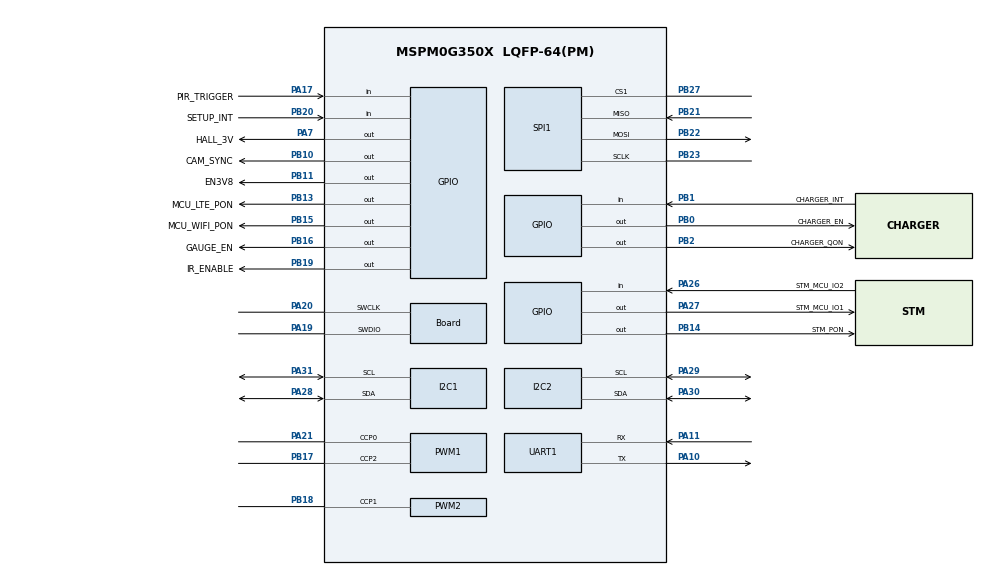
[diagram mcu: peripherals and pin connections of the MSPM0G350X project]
/**
 * @cliArgs --device "MSPM0G350X" --part "Default" --package "LQFP-64(PM)" --product "mspm0_sdk@2.09.00.01"
 * @versions {"tool":"1.25.0+4268"}
 */

/**
 * Import the modules used in this configuration.
 */
const Board  = scripting.addModule("/ti/driverlib/Board");
const GPIO   = scripting.addModule("/ti/driverlib/GPIO", {}, false);
const GPIO1  = GPIO.addInstance();
const GPIO2  = GPIO.addInstance();
const GPIO3  = GPIO.addInstance();
const I2C    = scripting.addModule("/ti/driverlib/I2C", {}, false);
const I2C1   = I2C.addInstance();
const I2C2   = I2C.addInstance();
const PWM    = scripting.addModule("/ti/driverlib/PWM", {}, false);
const PWM1   = PWM.addInstance();
const PWM2   = PWM.addInstance();
const RTC    = scripting.addModule("/ti/driverlib/RTC");
const SPI    = scripting.addModule("/ti/driverlib/SPI", {}, false);
const SPI1   = SPI.addInstance();
const SYSCTL = scripting.addModule("/ti/driverlib/SYSCTL");
const UART   = scripting.addModule("/ti/driverlib/UART", {}, false);
const UART1  = UART.addInstance();

/**
 * Write custom configuration values to the imported modules.
 */
const mux5       = system.clockTree["EXLFMUX"];
mux5.inputSelect = "EXLFMUX_XTAL";

const pinFunction6     = system.clockTree["LFXT"];
pinFunction6.enable    = true;
pinFunction6.inputFreq = 32.768;

Board.peripheral.swclkPin.$assign = "PA20";
Board.peripheral.swdioPin.$assign = "PA19";

GPIO1.$name                              = "EXTERNAL_INTERRUPT";
GPIO1.associatedPins.create(4);
GPIO1.associatedPins[0].$name            = "CHARGER_INT";
GPIO1.associatedPins[0].direction        = "INPUT";
GPIO1.associatedPins[0].assignedPin      = "any";
GPIO1.associatedPins[0].ioStructure      = "SD";
GPIO1.associatedPins[0].polarity         = "FALL";
GPIO1.associatedPins[0].pin.$assign      = "PB1";
GPIO1.associatedPins[1].$name            = "SETUP_INT";
GPIO1.associatedPins[1].direction        = "INPUT";
GPIO1.associatedPins[1].assignedPort     = "PORTB";
GPIO1.associatedPins[1].assignedPin      = "any";
GPIO1.associatedPins[1].interruptEn      = true;
GPIO1.associatedPins[1].polarity         = "FALL";
GPIO1.associatedPins[1].pin.$assign      = "PB20";
GPIO1.associatedPins[2].$name            = "STM_MCU_IO2";
GPIO1.associatedPins[2].direction        = "INPUT";
GPIO1.associatedPins[2].internalResistor = "PULL_DOWN";
GPIO1.associatedPins[2].interruptEn      = true;
GPIO1.associatedPins[2].polarity         = "RISE_FALL";
GPIO1.associatedPins[2].pin.$assign      = "PA26";
GPIO1.associatedPins[3].$name            = "PIR_TRIGGER";
GPIO1.associatedPins[3].direction        = "INPUT";
GPIO1.associatedPins[3].ioStructure      = "SDW";
GPIO1.associatedPins[3].assignedPort     = "PORTA";
GPIO1.associatedPins[3].interruptEn      = true;
GPIO1.associatedPins[3].polarity         = "FALL";
GPIO1.associatedPins[3].pin.$assign      = "PA17";

GPIO2.$name                          = "DIGITAL_OUTPUT_PORTB";
GPIO2.port                           = "PORTB";
GPIO2.associatedPins.create(9);
GPIO2.associatedPins[0].$name        = "CHARGER_EN";
GPIO2.associatedPins[0].ioStructure  = "SD";
GPIO2.associatedPins[0].assignedPin  = "0";
GPIO2.associatedPins[0].initialValue = "SET";
GPIO2.associatedPins[0].pin.$assign  = "PB0";
GPIO2.associatedPins[1].$name        = "CHARGER_QON";
GPIO2.associatedPins[1].ioStructure  = "SD";
GPIO2.associatedPins[1].assignedPin  = "2";
GPIO2.associatedPins[1].initialValue = "SET";
GPIO2.associatedPins[1].pin.$assign  = "PB2";
GPIO2.associatedPins[2].assignedPin  = "11";
GPIO2.associatedPins[2].ioStructure  = "SD";
GPIO2.associatedPins[2].$name        = "EN3V8";
GPIO2.associatedPins[2].pin.$assign  = "PB11";
GPIO2.associatedPins[3].$name        = "MCU_LTE_PON";
GPIO2.associatedPins[3].ioStructure  = "SD";
GPIO2.associatedPins[3].assignedPin  = "13";
GPIO2.associatedPins[3].pin.$assign  = "PB13";
GPIO2.associatedPins[4].$name        = "STM_PON";
GPIO2.associatedPins[4].ioStructure  = "SD";
GPIO2.associatedPins[4].assignedPin  = "14";
GPIO2.associatedPins[4].pin.$assign  = "PB14";
GPIO2.associatedPins[5].ioStructure  = "SD";
GPIO2.associatedPins[5].assignedPin  = "15";
GPIO2.associatedPins[5].$name        = "MCU_WIFI_PON";
GPIO2.associatedPins[5].pin.$assign  = "PB15";
GPIO2.associatedPins[6].$name        = "CAM_SYNC";
GPIO2.associatedPins[6].ioStructure  = "SD";
GPIO2.associatedPins[6].assignedPin  = "10";
GPIO2.associatedPins[6].pin.$assign  = "PB10";
GPIO2.associatedPins[7].$name        = "GAUGE_EN";
GPIO2.associatedPins[7].pin.$assign  = "PB16";
GPIO2.associatedPins[8].$name        = "IR_ENABLE";
GPIO2.associatedPins[8].pin.$assign  = "PB19";

GPIO3.$name                              = "DIGITAL_OUTPUT_PORTA";
GPIO3.port                               = "PORTA";
GPIO3.associatedPins.create(2);
GPIO3.associatedPins[0].$name            = "HALL_3V";
GPIO3.associatedPins[0].pin.$assign      = "PA7";
GPIO3.associatedPins[1].$name            = "STM_MCU_IO1";
GPIO3.associatedPins[1].internalResistor = "PULL_DOWN";
GPIO3.associatedPins[1].pin.$assign      = "PA27";

I2C1.$name                         = "I2C_0";
I2C1.basicEnableController         = true;
I2C1.intController                 = ["ARBITRATION_LOST","NACK","RXFIFO_TRIGGER","RX_DONE","TXFIFO_TRIGGER","TX_DONE"];
I2C1.peripheral.$assign            = "I2C0";
I2C1.peripheral.sdaPin.$assign     = "PA28";
I2C1.peripheral.sclPin.$assign     = "PA31";
I2C1.sdaPinConfig.$name            = "ti_driverlib_gpio_GPIOPinGeneric9";
I2C1.sdaPinConfig.internalResistor = "PULL_UP";
I2C1.sdaPinConfig.enableConfig     = true;
I2C1.sclPinConfig.$name            = "ti_driverlib_gpio_GPIOPinGeneric10";
I2C1.sclPinConfig.internalResistor = "PULL_UP";
I2C1.sclPinConfig.enableConfig     = true;

I2C2.$name                         = "I2C_1";
I2C2.basicEnableController         = true;
I2C2.intController                 = ["ARBITRATION_LOST","NACK","RXFIFO_TRIGGER","RX_DONE","TXFIFO_TRIGGER","TX_DONE"];
I2C2.peripheral.$assign            = "I2C1";
I2C2.peripheral.sdaPin.$assign     = "PA30";
I2C2.peripheral.sclPin.$assign     = "PA29";
I2C2.sdaPinConfig.$name            = "ti_driverlib_gpio_GPIOPinGeneric11";
I2C2.sdaPinConfig.internalResistor = "PULL_UP";
I2C2.sdaPinConfig.enableConfig     = true;
I2C2.sclPinConfig.$name            = "ti_driverlib_gpio_GPIOPinGeneric12";
I2C2.sclPinConfig.internalResistor = "PULL_UP";
I2C2.sclPinConfig.enableConfig     = true;

PWM1.$name                              = "BOOST_CONTROL";
PWM1.clockDivider                       = 8;
PWM1.timerCount                         = 100;
PWM1.ccIndex                            = [0,2];
PWM1.PWM_CHANNEL_0.$name                = "ti_driverlib_pwm_PWMTimerCC0";
PWM1.PWM_CHANNEL_0.ccValue              = 99;
PWM1.ccp0PinConfig.direction            = scripting.forceWrite("OUTPUT");
PWM1.ccp0PinConfig.hideOutputInversion  = scripting.forceWrite(false);
PWM1.ccp0PinConfig.onlyInternalResistor = scripting.forceWrite(false);
PWM1.ccp0PinConfig.passedPeripheralType = scripting.forceWrite("Digital");
PWM1.ccp0PinConfig.$name                = "ti_driverlib_gpio_GPIOPinGeneric0";
PWM1.ccp0PinConfig.enableConfig         = true;
PWM1.ccp0PinConfig.internalResistor     = "PULL_DOWN";
PWM1.peripheral.ccp0Pin.$assign         = "PA21";
PWM1.peripheral.ccp2Pin.$assign         = "PB17";
PWM1.PWM_CHANNEL_2.$name                = "ti_driverlib_pwm_PWMTimerCC1";
PWM1.PWM_CHANNEL_2.ccValue              = 99;
PWM1.ccp2PinConfig.$name                = "ti_driverlib_gpio_GPIOPinGeneric1";

PWM2.$name                              = "FLASH_CONTROL";
PWM2.clockDivider                       = 8;
PWM2.timerCount                         = 20000;
PWM2.pwmMode                            = "EDGE_ALIGN_UP";
PWM2.ccIndex                            = [1];
PWM2.ccp1PinConfig.direction            = scripting.forceWrite("OUTPUT");
PWM2.ccp1PinConfig.hideOutputInversion  = scripting.forceWrite(false);
PWM2.ccp1PinConfig.onlyInternalResistor = scripting.forceWrite(false);
PWM2.ccp1PinConfig.passedPeripheralType = scripting.forceWrite("Digital");
PWM2.ccp1PinConfig.$name                = "ti_driverlib_gpio_GPIOPinGeneric2";
PWM2.peripheral.$assign                 = "TIMA1";
PWM2.peripheral.ccp1Pin.$assign         = "PB18";
PWM2.PWM_CHANNEL_1.$name                = "ti_driverlib_pwm_PWMTimerCC2";
PWM2.PWM_CHANNEL_1.dutyCycle            = 20;

RTC.enIntervalAlarm   = true;
RTC.enabledInterrupts = ["INTERVAL_ALARM","PRESCALER1"];
RTC.enPerAlarm1       = true;
RTC.perAlarm1Divider  = "DIVIDE_128";
RTC.enableClock       = true;
RTC.calHour           = 2;
RTC.calMin            = 1;
RTC.calSec            = 1;
RTC.calDOW            = "4";
RTC.calMonth          = "6";
RTC.calYear           = 2000;

SPI1.$name                                 = "SPI_1";
SPI1.peripheralChipSelect                  = "1";
SPI1.rxFifoThreshold                       = "DL_SPI_RX_FIFO_LEVEL_ONE_FRAME";
SPI1.txFifoThreshold                       = "DL_SPI_TX_FIFO_LEVEL_ONE_FRAME";
SPI1.enabledInterrupts                     = ["DMA_DONE_RX","DMA_DONE_TX","TX_EMPTY"];
SPI1.enabledDMAEvent1Triggers              = "DL_SPI_DMA_INTERRUPT_RX";
SPI1.enabledDMAEvent2Triggers              = "DL_SPI_DMA_INTERRUPT_TX";
SPI1.chipSelect                            = ["1"];
SPI1.targetBitRate                         = 10000;
SPI1.sclkPinConfig.direction               = scripting.forceWrite("OUTPUT");
SPI1.sclkPinConfig.onlyInternalResistor    = scripting.forceWrite(false);
SPI1.sclkPinConfig.passedPeripheralType    = scripting.forceWrite("Digital");
SPI1.sclkPinConfig.$name                   = "ti_driverlib_gpio_GPIOPinGeneric5";
SPI1.mosiPinConfig.direction               = scripting.forceWrite("OUTPUT");
SPI1.mosiPinConfig.hideOutputInversion     = scripting.forceWrite(false);
SPI1.mosiPinConfig.onlyInternalResistor    = scripting.forceWrite(false);
SPI1.mosiPinConfig.passedPeripheralType    = scripting.forceWrite("Digital");
SPI1.mosiPinConfig.$name                   = "ti_driverlib_gpio_GPIOPinGeneric6";
SPI1.misoPinConfig.onlyInternalResistor    = scripting.forceWrite(false);
SPI1.misoPinConfig.passedPeripheralType    = scripting.forceWrite("Digital");
SPI1.misoPinConfig.$name                   = "ti_driverlib_gpio_GPIOPinGeneric7";
SPI1.DMA_CHANNEL_EVENT1.addressMode        = "f2b";
SPI1.DMA_CHANNEL_EVENT1.srcLength          = "BYTE";
SPI1.DMA_CHANNEL_EVENT1.dstLength          = "BYTE";
SPI1.DMA_CHANNEL_EVENT1.$name              = "DMA_CH1";
SPI1.DMA_CHANNEL_EVENT1.peripheral.$assign = "DMA_CH1";
SPI1.DMA_CHANNEL_EVENT2.dstLength          = "BYTE";
SPI1.DMA_CHANNEL_EVENT2.srcLength          = "BYTE";
SPI1.DMA_CHANNEL_EVENT2.$name              = "DMA_CH0";
SPI1.DMA_CHANNEL_EVENT2.addressMode        = "b2f";
SPI1.DMA_CHANNEL_EVENT2.peripheral.$assign = "DMA_CH0";
SPI1.peripheral.$assign                    = "SPI1";
SPI1.peripheral.sclkPin.$assign            = "PB23";
SPI1.peripheral.mosiPin.$assign            = "PB22";
SPI1.peripheral.misoPin.$assign            = "PB21";
SPI1.peripheral.cs1Pin.$assign             = "PB27";
SPI1.cs1PinConfig.$name                    = "ti_driverlib_gpio_GPIOPinGeneric8";

SYSCTL.VDD                   = 3;
SYSCTL.forceDefaultClkConfig = true;
SYSCTL.clockTreeEn           = true;
SYSCTL.powerPolicy           = "STANDBY0";

UART1.$name                    = "UART_0";
UART1.enabledInterrupts        = ["RX","TX"];
UART1.uartClkSrc               = "LFCLK";
UART1.ovsRate                  = "3";
UART1.peripheral.$assign       = "UART0";
UART1.peripheral.rxPin.$assign = "PA11";
UART1.peripheral.txPin.$assign = "PA10";
UART1.txPinConfig.$name        = "ti_driverlib_gpio_GPIOPinGeneric13";
UART1.rxPinConfig.$name        = "ti_driverlib_gpio_GPIOPinGeneric14";

/**
 * Pinmux solution for unlocked pins/peripherals. This ensures that minor changes to the automatic solver in a future
 * version of the tool will not impact the pinmux you originally saw.  These lines can be completely deleted in order to
 * re-solve from scratch.
 */
pinFunction6.peripheral.$suggestSolution           = "SYSCTL";
pinFunction6.peripheral.lfxInPin.$suggestSolution  = "PA3";
pinFunction6.peripheral.lfxOutPin.$suggestSolution = "PA4";
Board.peripheral.$suggestSolution                  = "DEBUGSS";
PWM1.peripheral.$suggestSolution                   = "TIMA0";
RTC.peripheral.$suggestSolution                    = "RTC";
